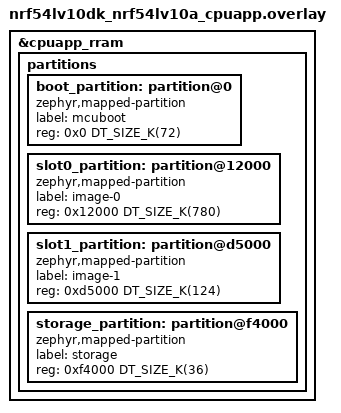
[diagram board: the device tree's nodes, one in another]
/delete-node/ &boot_partition;
/delete-node/ &slot0_partition;
/delete-node/ &slot1_partition;
/delete-node/ &storage_partition;

&cpuapp_rram {
	partitions {
		boot_partition: partition@0 {
			compatible = "zephyr,mapped-partition";
			label = "mcuboot";
			reg = <0x0 DT_SIZE_K(72)>;
		};

		slot0_partition: partition@12000 {
			compatible = "zephyr,mapped-partition";
			label = "image-0";
			reg = <0x12000 DT_SIZE_K(780)>;
		};

		slot1_partition: partition@d5000 {
			compatible = "zephyr,mapped-partition";
			label = "image-1";
			reg = <0xd5000 DT_SIZE_K(124)>;
		};

		storage_partition: partition@f4000 {
			compatible = "zephyr,mapped-partition";
			label = "storage";
			reg = <0xf4000 DT_SIZE_K(36)>;
		};
	};
};
